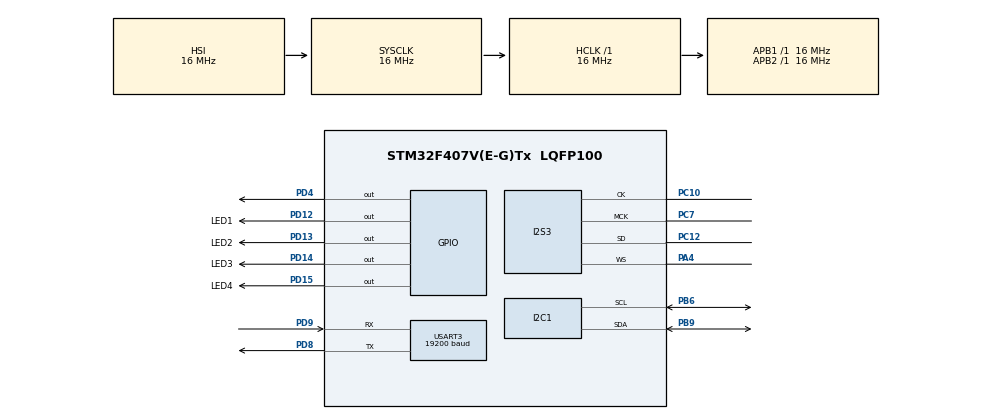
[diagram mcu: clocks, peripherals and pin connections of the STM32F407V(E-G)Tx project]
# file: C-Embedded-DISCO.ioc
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Dma.Request0=SPI3_TX
Dma.SPI3_TX.0.Direction=DMA_MEMORY_TO_PERIPH
Dma.SPI3_TX.0.FIFOMode=DMA_FIFOMODE_ENABLE
Dma.SPI3_TX.0.FIFOThreshold=DMA_FIFO_THRESHOLD_FULL
Dma.SPI3_TX.0.Instance=DMA1_Stream5
Dma.SPI3_TX.0.MemBurst=DMA_MBURST_SINGLE
Dma.SPI3_TX.0.MemDataAlignment=DMA_MDATAALIGN_HALFWORD
Dma.SPI3_TX.0.MemInc=DMA_MINC_ENABLE
Dma.SPI3_TX.0.Mode=DMA_NORMAL
Dma.SPI3_TX.0.PeriphBurst=DMA_PBURST_SINGLE
Dma.SPI3_TX.0.PeriphDataAlignment=DMA_PDATAALIGN_HALFWORD
Dma.SPI3_TX.0.PeriphInc=DMA_PINC_DISABLE
Dma.SPI3_TX.0.Priority=DMA_PRIORITY_LOW
I2S3.AudioFreq=I2S_AUDIOFREQ_48K
I2S3.ErrorAudioFreq=-2.34 %
I2S3.FullDuplexMode=I2S_FULLDUPLEXMODE_DISABLE
I2S3.Instance=SPI$Index
I2S3.RealAudioFreq=46.875 KHz
I2S3.VirtualMode=I2S_MODE_MASTER
Mcu.Family=STM32F4
Mcu.Name=STM32F407V(E-G)Tx
Mcu.Package=LQFP100
NVIC.DMA1_Stream5_IRQn=true\:0\:0\:false\:true\:true\:2\:false\:true\:true
NVIC.PriorityGroup=NVIC_PRIORITYGROUP_4
NVIC.SPI3_IRQn=true\:0\:0\:false\:false\:true\:true\:true\:true
NVIC.USART3_IRQn=true\:0\:0\:false\:true\:true\:1\:true\:true\:true
PA13.Mode=Serial_Wire
PA13.Signal=SYS_JTMS-SWDIO
PA14.Mode=Serial_Wire
PA14.Signal=SYS_JTCK-SWCLK
PA4.Mode=Half_Duplex_Master
PA4.Signal=I2S3_WS
PB6.Mode=I2C
PB6.Signal=I2C1_SCL
PB9.Mode=I2C
PB9.Signal=I2C1_SDA
PC10.Mode=Half_Duplex_Master
PC10.Signal=I2S3_CK
PC12.Mode=Half_Duplex_Master
PC12.Signal=I2S3_SD
PC7.Mode=Master_Clock_Activated
PC7.Signal=I2S3_MCK
PD12.GPIO_Label=LED1
PD12.Signal=GPIO_Output
PD13.GPIO_Label=LED2
PD13.Signal=GPIO_Output
PD14.GPIO_Label=LED3
PD14.Signal=GPIO_Output
PD15.GPIO_Label=LED4
PD15.Signal=GPIO_Output
PD4.Signal=GPIO_Output
PD8.Mode=Asynchronous
PD8.Signal=USART3_TX
PD9.Mode=Asynchronous
PD9.Signal=USART3_RX
ProjectManager.HeapSize=0x200
ProjectManager.StackSize=0x400
ProjectManager.TargetToolchain=CMake
RCC.AHBFreq_Value=16000000
RCC.APB1Freq_Value=16000000
RCC.APB2Freq_Value=16000000
RCC.CortexFreq_Value=16000000
RCC.HSE_VALUE=25000000
RCC.HSI_VALUE=16000000
RCC.LSE_VALUE=32768
RCC.SYSCLKFreq_VALUE=16000000
RCC.VCOOutputFreq_Value=192000000
USART3.BaudRate=19200
USART3.VirtualMode=VM_ASYNC
board=custom

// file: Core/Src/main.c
/* USER CODE BEGIN Header */
/**
 ******************************************************************************
 * @file           : main.c
 * @brief          : Main program body
 ******************************************************************************
 * @attention
 *
 * Copyright (c) 2025 STMicroelectronics.
 * All rights reserved.
 *
 * This software is licensed under terms that can be found in the LICENSE file
 * in the root directory of this software component.
 * If no LICENSE file comes with this software, it is provided AS-IS.
 *
 ******************************************************************************
 */
/* USER CODE END Header */
#include "main.h"

/* USER CODE BEGIN Includes */
#include "string.h"
#include "CS43L22.h"
#include "math.h"
/* USER CODE END Includes */

/* USER CODE BEGIN PTD */
typedef void (*usart_command_f)(void);
/* USER CODE END PTD */

/* USER CODE BEGIN PD */
#define USART1_RX_LEN       (32)
#define USART1_TX_LEN       (32)
#define USART1_NUM_COMMANDS (6)
/* USER CODE END PD */

/* USER CODE BEGIN PM */
#define F_SAMPLE 96000.0f
#define F_OUT    2000.0f
#define PI       3.14159f
/* USER CODE END PM */

I2C_HandleTypeDef hi2c1;

I2S_HandleTypeDef hi2s3;
DMA_HandleTypeDef hdma_spi3_tx;

UART_HandleTypeDef huart3;

void SystemClock_Config(void);
static void MX_GPIO_Init(void);
static void MX_DMA_Init(void);
static void MX_USART3_UART_Init(void);
static void MX_I2C1_Init(void);
static void MX_I2S3_Init(void);
static void MX_NVIC_Init(void);

int main(void)
{

  /* MCU Configuration--------------------------------------------------------*/

  /* Reset of all peripherals, Initializes the Flash interface and the Systick. */
  HAL_Init();

  /* Configure the system clock */
  SystemClock_Config();

  /* Initialize all configured peripherals */
  MX_GPIO_Init();
  MX_DMA_Init();
  MX_USART3_UART_Init();
  MX_I2C1_Init();
  MX_I2S3_Init();

  /* Initialize interrupts */
  MX_NVIC_Init();
  /* USER CODE BEGIN 2 */
  CS43L22_Init(&hi2c1);

  /* Start codec */
  CS43L22_Start(&hi2c1);

  uint16_t i2s_data[256];

  /* Infinite loop */
  while (1) {
    /* Generate 1kHz sine (stereo) */
    for (int i = 0; i < 128; i++) {
      float t        = (float)i / 128.0f;
      int16_t sample = (int16_t)(sinf(t * 2.0f * 3.14159f) * 28000);

      i2s_data[i * 2 + 0] = sample;  // Left
      i2s_data[i * 2 + 1] = sample;  // Right
    }

    HAL_I2S_Transmit_DMA(&hi2s3, i2s_data, 256);
    HAL_Delay(1000);
  }
}

void SystemClock_Config(void)
{
  RCC_OscInitTypeDef RCC_OscInitStruct = {0};
  RCC_ClkInitTypeDef RCC_ClkInitStruct = {0};

  /** Macro to configure the PLL multiplication factor
   */
  __HAL_RCC_PLL_PLLM_CONFIG(16);

  /** Macro to configure the PLL clock source
   */
  __HAL_RCC_PLL_PLLSOURCE_CONFIG(RCC_PLLSOURCE_HSI);

  /** Configure the main internal regulator output voltage
   */
  __HAL_RCC_PWR_CLK_ENABLE();
  __HAL_PWR_VOLTAGESCALING_CONFIG(PWR_REGULATOR_VOLTAGE_SCALE1);

  /** Initializes the RCC Oscillators according to the specified parameters
   * in the RCC_OscInitTypeDef structure.
   */
  RCC_OscInitStruct.OscillatorType      = RCC_OSCILLATORTYPE_HSI;
  RCC_OscInitStruct.HSIState            = RCC_HSI_ON;
  RCC_OscInitStruct.HSICalibrationValue = RCC_HSICALIBRATION_DEFAULT;
  RCC_OscInitStruct.PLL.PLLState        = RCC_PLL_NONE;
  RCC_OscInitStruct.PLL.PLLSource       = RCC_PLLSOURCE_HSI;
  if (HAL_RCC_OscConfig(&RCC_OscInitStruct) != HAL_OK) {
    Error_Handler();
  }

  /** Initializes the CPU, AHB and APB buses clocks
   */
  RCC_ClkInitStruct.ClockType      = RCC_CLOCKTYPE_HCLK | RCC_CLOCKTYPE_SYSCLK | RCC_CLOCKTYPE_PCLK1 | RCC_CLOCKTYPE_PCLK2;
  RCC_ClkInitStruct.SYSCLKSource   = RCC_SYSCLKSOURCE_HSI;
  RCC_ClkInitStruct.AHBCLKDivider  = RCC_SYSCLK_DIV1;
  RCC_ClkInitStruct.APB1CLKDivider = RCC_HCLK_DIV1;
  RCC_ClkInitStruct.APB2CLKDivider = RCC_HCLK_DIV1;

  if (HAL_RCC_ClockConfig(&RCC_ClkInitStruct, FLASH_LATENCY_0) != HAL_OK) {
    Error_Handler();
  }
}

/**
 * @brief NVIC Configuration.
 * @retval None
 */
static void MX_NVIC_Init(void)
{
  /* USART3_IRQn interrupt configuration */
  HAL_NVIC_SetPriority(USART3_IRQn, 0, 0);
  HAL_NVIC_EnableIRQ(USART3_IRQn);
}

static void MX_I2C1_Init(void)
{

  hi2c1.Instance             = I2C1;
  hi2c1.Init.ClockSpeed      = 100000;
  hi2c1.Init.DutyCycle       = I2C_DUTYCYCLE_2;
  hi2c1.Init.OwnAddress1     = 0;
  hi2c1.Init.AddressingMode  = I2C_ADDRESSINGMODE_7BIT;
  hi2c1.Init.DualAddressMode = I2C_DUALADDRESS_DISABLE;
  hi2c1.Init.OwnAddress2     = 0;
  hi2c1.Init.GeneralCallMode = I2C_GENERALCALL_DISABLE;
  hi2c1.Init.NoStretchMode   = I2C_NOSTRETCH_DISABLE;
  if (HAL_I2C_Init(&hi2c1) != HAL_OK) {
    Error_Handler();
  }
}

static void MX_I2S3_Init(void)
{

  hi2s3.Instance            = SPI3;
  hi2s3.Init.Mode           = I2S_MODE_MASTER_TX;
  hi2s3.Init.Standard       = I2S_STANDARD_PHILIPS;
  hi2s3.Init.DataFormat     = I2S_DATAFORMAT_16B;
  hi2s3.Init.MCLKOutput     = I2S_MCLKOUTPUT_ENABLE;
  hi2s3.Init.AudioFreq      = I2S_AUDIOFREQ_48K;
  hi2s3.Init.CPOL           = I2S_CPOL_LOW;
  hi2s3.Init.ClockSource    = I2S_CLOCK_PLL;
  hi2s3.Init.FullDuplexMode = I2S_FULLDUPLEXMODE_DISABLE;
  if (HAL_I2S_Init(&hi2s3) != HAL_OK) {
    Error_Handler();
  }
}

static void MX_USART3_UART_Init(void)
{

  huart3.Instance          = USART3;
  huart3.Init.BaudRate     = 19200;
  huart3.Init.WordLength   = UART_WORDLENGTH_8B;
  huart3.Init.StopBits     = UART_STOPBITS_1;
  huart3.Init.Parity       = UART_PARITY_NONE;
  huart3.Init.Mode         = UART_MODE_TX_RX;
  huart3.Init.HwFlowCtl    = UART_HWCONTROL_NONE;
  huart3.Init.OverSampling = UART_OVERSAMPLING_16;
  if (HAL_UART_Init(&huart3) != HAL_OK) {
    Error_Handler();
  }
}

static void MX_DMA_Init(void)
{
  /* DMA controller clock enable */
  __HAL_RCC_DMA1_CLK_ENABLE();

  /* DMA interrupt init */
  /* DMA1_Stream5_IRQn interrupt configuration */
  HAL_NVIC_SetPriority(DMA1_Stream5_IRQn, 0, 0);
  HAL_NVIC_EnableIRQ(DMA1_Stream5_IRQn);
}

static void MX_GPIO_Init(void)
{
  GPIO_InitTypeDef GPIO_InitStruct = {0};

  /* GPIO Ports Clock Enable */
  __HAL_RCC_GPIOA_CLK_ENABLE();
  __HAL_RCC_GPIOD_CLK_ENABLE();
  __HAL_RCC_GPIOC_CLK_ENABLE();
  __HAL_RCC_GPIOB_CLK_ENABLE();

  /*Configure GPIO pin Output Level */
  HAL_GPIO_WritePin(GPIOD, LED1_Pin | LED2_Pin | LED3_Pin | LED4_Pin | GPIO_PIN_4, GPIO_PIN_RESET);

  /*Configure GPIO pins : LED1_Pin LED2_Pin LED3_Pin LED4_Pin
                           PD4 */
  GPIO_InitStruct.Pin   = LED1_Pin | LED2_Pin | LED3_Pin | LED4_Pin | GPIO_PIN_4;
  GPIO_InitStruct.Mode  = GPIO_MODE_OUTPUT_PP;
  GPIO_InitStruct.Pull  = GPIO_NOPULL;
  GPIO_InitStruct.Speed = GPIO_SPEED_FREQ_LOW;
  HAL_GPIO_Init(GPIOD, &GPIO_InitStruct);

}

void Error_Handler(void)
{
  __disable_irq();
  while (1) {
  }
}
